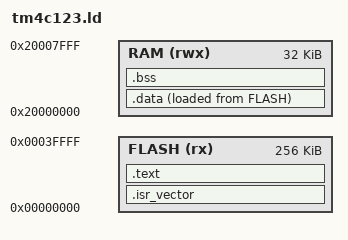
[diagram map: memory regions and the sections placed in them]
ENTRY(Reset_Handler)

MEMORY
{
    FLASH (rx)  : ORIGIN = 0x00000000, LENGTH = 256K
    RAM   (rwx) : ORIGIN = 0x20000000, LENGTH = 32K
}

_estack = ORIGIN(RAM) + LENGTH(RAM);

SECTIONS
{
    .isr_vector :
    {
        KEEP(*(.isr_vector))
    } > FLASH

    .text :
    {
        *(.text*)
        *(.rodata*)
        *(.init)
        *(.fini)

        . = ALIGN(4);
        _etext = .;
    } > FLASH

    _la_data = LOADADDR(.data);

    .data :
    {
        . = ALIGN(4);

        _sdata = .;

        *(.data*)

        . = ALIGN(4);

        _edata = .;
    } > RAM AT > FLASH

    .bss :
    {
        . = ALIGN(4);

        _sbss = .;

        *(.bss*)
        *(COMMON)

        . = ALIGN(4);

        _ebss = .;
    } > RAM
}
